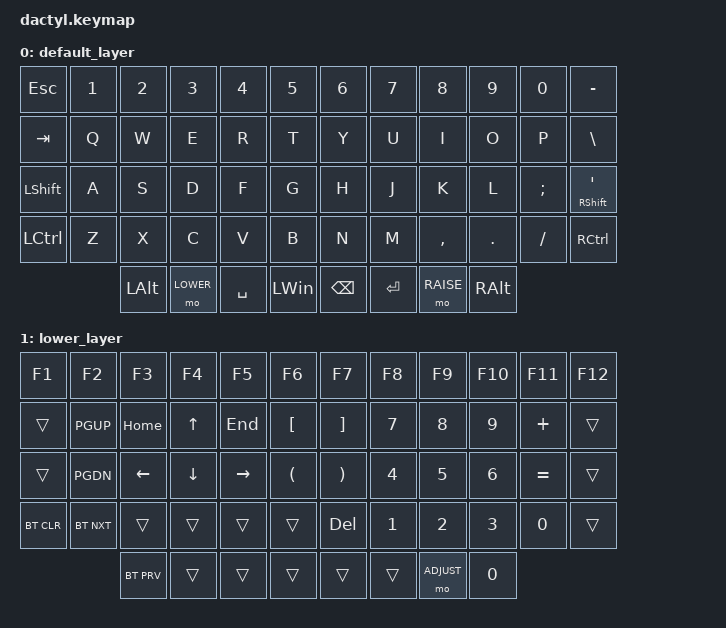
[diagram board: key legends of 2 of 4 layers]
#include <behaviors.dtsi>
#include <dt-bindings/zmk/keys.h>
#include <dt-bindings/zmk/bt.h>
#include <dt-bindings/zmk/outputs.h>
#include <dt-bindings/zmk/mouse.h>

#define DEFAULT 0
#define LOWER 1
#define RAISE 2
#define ADJUST 3

/ {
    keymap {
        compatible = "zmk,keymap";

        default_layer {
            bindings = <
                &kp ESC &kp N1  &kp N2    &kp N3    &kp N4    &kp N5 &kp N6	&kp N7	&kp N8	&kp N9	&kp N0	&kp MINUS
				&kp TAB &kp Q  &kp W &kp E &kp R &kp T &kp Y &kp U &kp I &kp O &kp P &kp BACKSLASH
                &kp LSHIFT  &kp A  &kp S    &kp D    &kp F    &kp G &kp H   &kp J   &kp K   &kp L   &kp SEMICOLON &mt RSHIFT APOSTROPHE
                &kp LCTRL &kp Z  &kp X    &kp C    &kp V    &kp B &kp N   &kp M   &kp COMMA &kp DOT &kp SLASH &kp RCTRL 
                       &kp LALT &mo LOWER &kp SPACE &kp LWIN  &kp BSPC &kp ENTER &mo RAISE &kp RALT                                                                                                                  
            >;
        };

      lower_layer {
            bindings = <
    &kp F1    &kp F2  &kp F3    &kp F4    &kp F5    &kp F6     			&kp F7    &kp F8      &kp F9    &kp F10    &kp F11    &kp F12
    &trans    &kp PGUP  &kp HOME    &kp UP    &kp END  &kp LBKT         &kp RBKT     &kp N7     &kp N8    &kp N9      &kp PLUS    &trans
    &trans    &kp PGDN  &kp LEFT  &kp DOWN  &kp RIGHT  &kp LPAR   		&kp RPAR     &kp N4     &kp N5    &kp N6   &kp EQUAL &trans
    &bt BT_CLR  &bt BT_NXT   &trans   &trans   &trans  &trans           		&kp DEL	  &kp N1      &kp N2   &kp N3	&kp N0   &trans                                                          
                  &bt BT_PRV    &trans     &trans     &trans                &trans    &trans    &mo ADJUST    &kp N0
            >;
        };

     raise_layer {
            bindings = <
                &kp GRAVE &kp EXCL &kp AT &kp HASH &kp DLLR &kp PRCNT		&kp CARET &kp AMPERSAND &kp STAR &kp LPAR &kp RPAR &kp UNDER                   
                &trans &kp PSCRN &trans &trans &trans                       &trans &trans &trans &trans &trans &trans
                &trans &kp K_VOL_UP  &kp K_PP &kp C_BRI_UP &trans &trans    &trans &trans &trans &trans &trans &trans 
                &kp K_MUTE &kp K_VOL_DN  &kp K_STOP2 &kp C_BRI_DN     		&trans &trans &trans &trans &trans &trans                                                    
                                     &trans &mo ADJUST &trans &trans			&trans &trans &trans &trans
            >;
        };

	adjust_layer {
            bindings = <
				&sys_reset    &none  &none &none  &none &none  							&none  &none  &none   &none  &none &none
                &out OUT_BLE  &bt BT_SEL 0 &bt BT_SEL 1 &bt BT_SEL 2  &bt BT_SEL 3     &none   &none   &none   &none  &none &none
                &out OUT_USB  &none        &none        &none  &none &none            &none   &none   &none    &none    &none &none
                &bt BT_CLR   &bt BT_CLR_ALL    &none    &none   &none &none           &none &none &none  &none &none  &studio_unlock
                                                      &none &none  &none &none        &none &none   &none &none
            >;
        };

	extra_layer_4 {
		status = "reserved";
	};

	extra_layer_5 {
		status = "reserved";
	};

	extra_layer_6 {
		status = "reserved";
	};

	};
};
